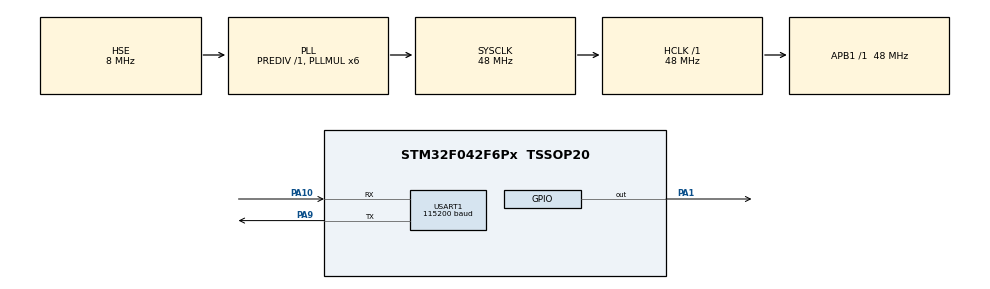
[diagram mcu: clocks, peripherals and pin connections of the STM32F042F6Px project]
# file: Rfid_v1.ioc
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Mcu.Family=STM32F0
Mcu.Name=STM32F042F6Px
Mcu.Package=TSSOP20
NVIC.USART1_IRQn=true\:0\:0\:false\:false\:true\:true\:true\:true
PA1.GPIO_Speed=GPIO_SPEED_FREQ_HIGH
PA1.PinState=GPIO_PIN_SET
PA1.Signal=GPIO_Output
PA10.Mode=Asynchronous
PA10.Signal=USART1_RX
PA9.Mode=Asynchronous
PA9.Signal=USART1_TX
PF0-OSC_IN.Mode=HSE-External-Oscillator
PF0-OSC_IN.Signal=RCC_OSC_IN
PF1-OSC_OUT.Mode=HSE-External-Oscillator
PF1-OSC_OUT.Signal=RCC_OSC_OUT
ProjectManager.HeapSize=0x200
ProjectManager.StackSize=0x400
ProjectManager.TargetToolchain=MDK-ARM V5.32
RCC.AHBFreq_Value=48000000
RCC.APB1Freq_Value=48000000
RCC.APB1TimFreq_Value=48000000
RCC.EnbaleCSS=true
RCC.HCLKFreq_Value=48000000
RCC.PLLMUL=RCC_PLL_MUL6
RCC.PLLSourceVirtual=RCC_PLLSOURCE_HSE
RCC.SYSCLKFreq_VALUE=48000000
RCC.SYSCLKSource=RCC_SYSCLKSOURCE_PLLCLK
USART1.BaudRate=115200
USART1.VirtualMode=VM_ASYNC
board=custom

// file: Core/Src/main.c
/* USER CODE BEGIN Header */
/**
  ******************************************************************************
  * @file           : main.c
  * @brief          : Main program body
  ******************************************************************************
  * @attention
  *
  * Copyright (c) 2025 STMicroelectronics.
  * All rights reserved.
  *
  * This software is licensed under terms that can be found in the LICENSE file
  * in the root directory of this software component.
  * If no LICENSE file comes with this software, it is provided AS-IS.
  *
  ******************************************************************************
  */
/* USER CODE END Header */
#include "main.h"
#include "usart.h"
#include "gpio.h"

void SystemClock_Config(void);

int main(void)
{

  /* MCU Configuration--------------------------------------------------------*/

  /* Reset of all peripherals, Initializes the Flash interface and the Systick. */
  HAL_Init();

  /* Configure the system clock */
  SystemClock_Config();

  /* Initialize all configured peripherals */
  MX_GPIO_Init();
	HAL_Delay(3000);
  MX_USART1_UART_Init();
  /* USER CODE BEGIN 2 */
 HAL_UART_Receive_IT(&huart1, rx_buffer, 13);  // 使能接收中断，初始接收13字节
  /* USER CODE END 2 */

  /* Infinite loop */
  while (1)
  {

  }
}

void SystemClock_Config(void)
{
  RCC_OscInitTypeDef RCC_OscInitStruct = {0};
  RCC_ClkInitTypeDef RCC_ClkInitStruct = {0};
  RCC_PeriphCLKInitTypeDef PeriphClkInit = {0};

  /** Initializes the RCC Oscillators according to the specified parameters
  * in the RCC_OscInitTypeDef structure.
  */
  RCC_OscInitStruct.OscillatorType = RCC_OSCILLATORTYPE_HSE;
  RCC_OscInitStruct.HSEState = RCC_HSE_ON;
  RCC_OscInitStruct.PLL.PLLState = RCC_PLL_ON;
  RCC_OscInitStruct.PLL.PLLSource = RCC_PLLSOURCE_HSE;
  RCC_OscInitStruct.PLL.PLLMUL = RCC_PLL_MUL6;
  RCC_OscInitStruct.PLL.PREDIV = RCC_PREDIV_DIV1;
  if (HAL_RCC_OscConfig(&RCC_OscInitStruct) != HAL_OK)
  {
    Error_Handler();
  }

  /** Initializes the CPU, AHB and APB buses clocks
  */
  RCC_ClkInitStruct.ClockType = RCC_CLOCKTYPE_HCLK|RCC_CLOCKTYPE_SYSCLK
                              |RCC_CLOCKTYPE_PCLK1;
  RCC_ClkInitStruct.SYSCLKSource = RCC_SYSCLKSOURCE_PLLCLK;
  RCC_ClkInitStruct.AHBCLKDivider = RCC_SYSCLK_DIV1;
  RCC_ClkInitStruct.APB1CLKDivider = RCC_HCLK_DIV1;

  if (HAL_RCC_ClockConfig(&RCC_ClkInitStruct, FLASH_LATENCY_1) != HAL_OK)
  {
    Error_Handler();
  }
  PeriphClkInit.PeriphClockSelection = RCC_PERIPHCLK_USART1;
  PeriphClkInit.Usart1ClockSelection = RCC_USART1CLKSOURCE_PCLK1;
  if (HAL_RCCEx_PeriphCLKConfig(&PeriphClkInit) != HAL_OK)
  {
    Error_Handler();
  }

  /** Enables the Clock Security System
  */
  HAL_RCC_EnableCSS();
}

void Error_Handler(void)
{
  __disable_irq();
  while (1)
  {
  }
}
